# MEC1723N_B0_LJ register map
Vendor: Microchip Technology; Series: MEC172x; File version: 0
CPU: CM4 r1p0, little endian, MPU, FPU, 3 interrupt priority bits, 172 interrupts
Registers are 32-bit, read-write, reset 0x0 unless marked. A register's access mark holds for its fields unless they carry their own. Offsets are from the block's base; [hi:lo] are bit positions.

## SAFBC_CACHE — SAF BRIDGE CACHE INTERFACE
Base 0x4000F000
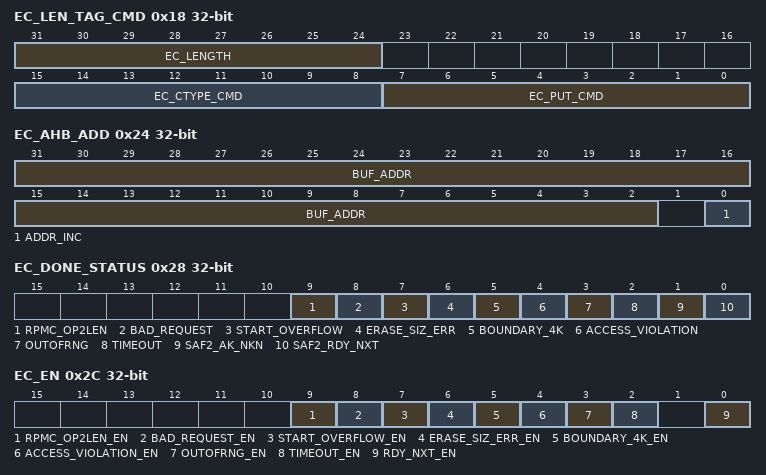
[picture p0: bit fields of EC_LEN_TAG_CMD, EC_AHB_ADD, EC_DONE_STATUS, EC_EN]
0x18 EC_LEN_TAG_CMD — This register defines the command type and length of transfers requested by EC firmware
  [31:24] EC_LENGTH — This field contains the Length field for all requests. Read or Write: The length in bytes of the data transfer, to or from the SRAM buffer. Must be in the range 1 -- 64 (01h -- 40h). Erase: Must encode an eSPI-defined Erase Block Size: 00h = 4K 01h = 32K 02h = 64K Other encodings are undefined.
  [15:8] EC_CTYPE_CMD — This field encodes the operation requested: 00h = Read 01h = Write (Page Program) 02h = Erase Other encodings are undefined
  [7:0] EC_PUT_CMD — This field must contain the value 0Ah; that is, the eSPI command PUT_FLASH_NP.
0x1C EC_FLASH_ADD — This register hold the Flash Space address to be accessed by the current command from EC firmware.
  [31:0] FLASH_ADDR — FLASH_ADDR: This field holds the Flash address to be accessed.
0x20 EC_START — This register contains the Start control for a Flash access requested in the rest of the EC Portal registers. It triggers the requested transfer.
  [0] START — This bit is written with '1' to start a new request, but always appears 0 when being read.
0x24 EC_AHB_ADD — This register holds a location in the EC's own address space that is to be used as the SRAM buffer for an EC Flash access.
  [31:2] BUF_ADDR — This field holds bits [31:2] of the SRAM buffer address. Bits[1:0] of the address are fixed at 00.
  [0] ADDR_INC — This bit controls whether the saf bridge increases the address in saf2_ahb_address.
0x28 EC_DONE_STATUS — This register holds the DONE status bit.
  [9] RPMC_OP2LEN — This bit indicates that a lenght greater that 49 is set for RPMC OP2 command. This is R/WC.
  [8] BAD_REQUEST — This bit indicates that an invalid Request code has been specified in the Portal Command Register at the time the START bit was set to trigger it. This is R/WC.
  [7] START_OVERFLOW — This bit indicates that an access was already in progress when a new access was requested by writing '1' to the START bit. This is R/WC.
  [6] ERASE_SIZ_ERR — This bit indicates that an invalid Erase Block Size has been specified in an Erase request. This is R/WC.
  [5] BOUNDARY_4K — This bit indicates that a Read request from the EC has been rejected because it has attempted to cross a 4K Flash address boundary. This bit is cleared by writing '1' to its position. This is R/WC.
  [4] ACCESS_VIOLATION — This bit indicates that a request from the EC has been rejected because it violates the Protection Register settings. This bit is cleared by writing '1' to its position. This is R/WC.
  [3] OUTOFRNG — This bit indicates that a request has been rejected because it is beyond the physical limits of the attached Flash devices. This bit is cleared by writing '1' to its position. This is R/WC.
  [2] TIMEOUT — This bit indicates that an Erase or Write request from the EC has failed because the Flash has timed out. This is R/WC.
  [1] SAF2_AK_NKN — This bit will always return 1 for f/w. This field is auto cleared by hardware. This is R/WC.
  [0] SAF2_RDY_NXT — When this bit is set the f/w initiated transaction is complete. This field is auto cleared by hardware. This is R/WC.
0x2C EC_EN — This register contains the one bit DONE_EN in bit position[0]. This bit enables the DONE bit in the status register to trigger an interrupt.
  [9] RPMC_OP2LEN_EN — This controls whether an interrupt is fired when RPMC OP2 Lenght is asserted.
  [8] BAD_REQUEST_EN — This controls whether an interrupt is fired when Bad Request is asserted.
  [7] START_OVERFLOW_EN — This controls whether an interrupt is fired when Start Overflow is asserted.
  [6] ERASE_SIZ_ERR_EN — This controls whether an interrupt is fired when Erase Size Error is asserted.
  [5] BOUNDARY_4K_EN — This controls whether an interrupt is fired when 4K Boundary is asserted.
  [4] ACCESS_VIOLATION_EN — This controls whether an interrupt is fired when Access Violation is asserted.
  [3] OUTOFRNG_EN — This controls whether an interrupt is fired when Out Of Range is asserted.
  [2] TIMEOUT_EN — This controls whether an interrupt is fired when Timeout is asserted.
  [0] RDY_NXT_EN — This bit controls whether an interrupt is fired when Ready_Next is asserted.
